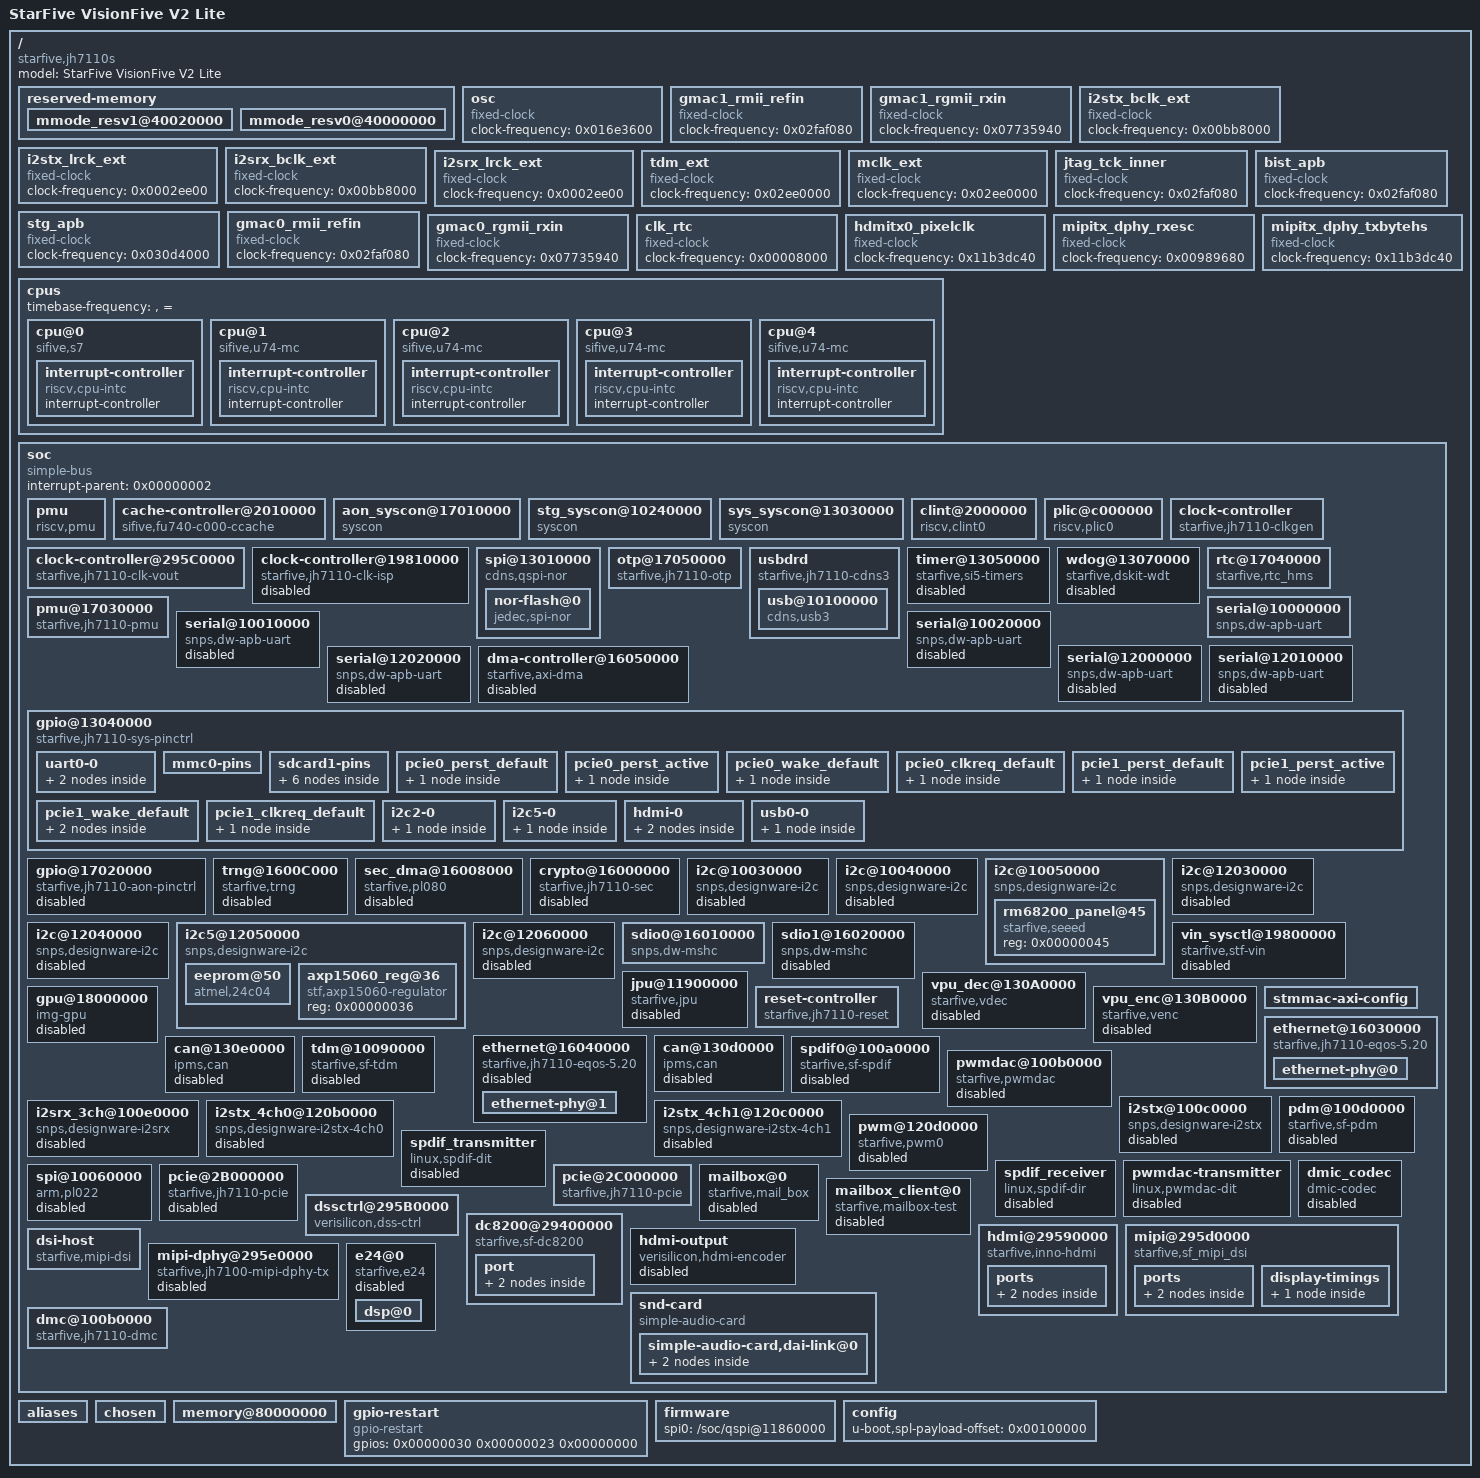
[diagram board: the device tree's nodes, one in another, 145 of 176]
/ {
	compatible = "starfive,jh7110s";
	#address-cells = <0x00000002>;
	#size-cells = <0x00000002>;
	model = "StarFive VisionFive V2 Lite";
	reserved-memory {
		#address-cells = <0x00000002>;
		#size-cells = <0x00000002>;
		ranges;
		mmode_resv1@40020000 {
			reg = <0x00000000 0x40020000 0x00000000 0x00020000>;
		};
		mmode_resv0@40000000 {
			reg = <0x00000000 0x40000000 0x00000000 0x00020000>;
		};
	};
	osc {
		compatible = "fixed-clock";
		#clock-cells = <0x00000000>;
		clock-frequency = <0x016e3600>;
		u-boot,dm-spl;
		phandle = <0x00000008>;
	};
	gmac1_rmii_refin {
		compatible = "fixed-clock";
		#clock-cells = <0x00000000>;
		clock-frequency = <0x02faf080>;
		u-boot,dm-spl;
		phandle = <0x00000009>;
	};
	gmac1_rgmii_rxin {
		compatible = "fixed-clock";
		#clock-cells = <0x00000000>;
		clock-frequency = <0x07735940>;
		phandle = <0x00000031>;
	};
	i2stx_bclk_ext {
		compatible = "fixed-clock";
		#clock-cells = <0x00000000>;
		clock-frequency = <0x00bb8000>;
		phandle = <0x00000032>;
	};
	i2stx_lrck_ext {
		compatible = "fixed-clock";
		#clock-cells = <0x00000000>;
		clock-frequency = <0x0002ee00>;
		phandle = <0x00000033>;
	};
	i2srx_bclk_ext {
		compatible = "fixed-clock";
		#clock-cells = <0x00000000>;
		clock-frequency = <0x00bb8000>;
		phandle = <0x00000034>;
	};
	i2srx_lrck_ext {
		compatible = "fixed-clock";
		#clock-cells = <0x00000000>;
		clock-frequency = <0x0002ee00>;
		phandle = <0x00000035>;
	};
	tdm_ext {
		compatible = "fixed-clock";
		#clock-cells = <0x00000000>;
		clock-frequency = <0x02ee0000>;
		phandle = <0x00000036>;
	};
	mclk_ext {
		compatible = "fixed-clock";
		#clock-cells = <0x00000000>;
		clock-frequency = <0x02ee0000>;
		phandle = <0x00000037>;
	};
	jtag_tck_inner {
		compatible = "fixed-clock";
		#clock-cells = <0x00000000>;
		clock-frequency = <0x02faf080>;
		phandle = <0x00000038>;
	};
	bist_apb {
		compatible = "fixed-clock";
		#clock-cells = <0x00000000>;
		clock-frequency = <0x02faf080>;
		phandle = <0x00000039>;
	};
	stg_apb {
		compatible = "fixed-clock";
		#clock-cells = <0x00000000>;
		clock-frequency = <0x030d4000>;
		u-boot,dm-spl;
		phandle = <0x0000000a>;
	};
	gmac0_rmii_refin {
		compatible = "fixed-clock";
		#clock-cells = <0x00000000>;
		clock-frequency = <0x02faf080>;
		u-boot,dm-spl;
		phandle = <0x0000000b>;
	};
	gmac0_rgmii_rxin {
		compatible = "fixed-clock";
		#clock-cells = <0x00000000>;
		clock-frequency = <0x07735940>;
		phandle = <0x0000003a>;
	};
	clk_rtc {
		compatible = "fixed-clock";
		#clock-cells = <0x00000000>;
		clock-frequency = <0x00008000>;
		phandle = <0x0000003b>;
	};
	hdmitx0_pixelclk {
		compatible = "fixed-clock";
		#clock-cells = <0x00000000>;
		clock-frequency = <0x11b3dc40>;
		phandle = <0x0000000c>;
	};
	mipitx_dphy_rxesc {
		compatible = "fixed-clock";
		#clock-cells = <0x00000000>;
		clock-frequency = <0x00989680>;
		phandle = <0x0000000d>;
	};
	mipitx_dphy_txbytehs {
		compatible = "fixed-clock";
		#clock-cells = <0x00000000>;
		clock-frequency = <0x11b3dc40>;
		phandle = <0x0000000e>;
	};
	cpus {
		#address-cells = <0x00000001>;
		#size-cells = <0x00000000>;
		u-boot,dm-spl;
		timebase-frequency = "", "=	";
		phandle = <0x0000003c>;
		cpu@0 {
			compatible = "sifive,s7", "riscv";
			reg = <0x00000000>;
			d-cache-block-size = <0x00000040>;
			d-cache-sets = <0x00000040>;
			d-cache-size = <0x00002000>;
			d-tlb-sets = <0x00000001>;
			d-tlb-size = <0x00000028>;
			device_type = "cpu";
			i-cache-block-size = <0x00000040>;
			i-cache-sets = <0x00000040>;
			i-cache-size = <0x00004000>;
			i-tlb-sets = <0x00000001>;
			i-tlb-size = <0x00000028>;
			mmu-type = "riscv,sv39";
			next-level-cache = <0x00000001>;
			riscv,isa = "rv64imacu_zba_zbb";
			tlb-split;
			status = "okay";
			u-boot,dm-spl;
			phandle = <0x0000003d>;
			interrupt-controller {
				#interrupt-cells = <0x00000001>;
				compatible = "riscv,cpu-intc";
				interrupt-controller;
				u-boot,dm-spl;
				phandle = <0x00000003>;
			};
		};
		cpu@1 {
			compatible = "sifive,u74-mc", "riscv";
			reg = <0x00000001>;
			d-cache-block-size = <0x00000040>;
			d-cache-sets = <0x00000040>;
			d-cache-size = <0x00008000>;
			d-tlb-sets = <0x00000001>;
			d-tlb-size = <0x00000028>;
			device_type = "cpu";
			i-cache-block-size = <0x00000040>;
			i-cache-sets = <0x00000040>;
			i-cache-size = <0x00008000>;
			i-tlb-sets = <0x00000001>;
			i-tlb-size = <0x00000028>;
			mmu-type = "riscv,sv39";
			next-level-cache = <0x00000001>;
			riscv,isa = "rv64imafdcbsux_zba_zbb";
			tlb-split;
			status = "okay";
			u-boot,dm-spl;
			phandle = <0x0000003e>;
			interrupt-controller {
				#interrupt-cells = <0x00000001>;
				compatible = "riscv,cpu-intc";
				interrupt-controller;
				u-boot,dm-spl;
				phandle = <0x00000004>;
			};
		};
		cpu@2 {
			compatible = "sifive,u74-mc", "riscv";
			reg = <0x00000002>;
			d-cache-block-size = <0x00000040>;
			d-cache-sets = <0x00000040>;
			d-cache-size = <0x00008000>;
			d-tlb-sets = <0x00000001>;
			d-tlb-size = <0x00000028>;
			device_type = "cpu";
			i-cache-block-size = <0x00000040>;
			i-cache-sets = <0x00000040>;
			i-cache-size = <0x00008000>;
			i-tlb-sets = <0x00000001>;
			i-tlb-size = <0x00000028>;
			mmu-type = "riscv,sv39";
			next-level-cache = <0x00000001>;
			riscv,isa = "rv64imafdcbsux_zba_zbb";
			tlb-split;
			status = "okay";
			u-boot,dm-spl;
			phandle = <0x0000003f>;
			interrupt-controller {
				#interrupt-cells = <0x00000001>;
				compatible = "riscv,cpu-intc";
				interrupt-controller;
				u-boot,dm-spl;
				phandle = <0x00000005>;
			};
		};
		cpu@3 {
			compatible = "sifive,u74-mc", "riscv";
			reg = <0x00000003>;
			d-cache-block-size = <0x00000040>;
			d-cache-sets = <0x00000040>;
			d-cache-size = <0x00008000>;
			d-tlb-sets = <0x00000001>;
			d-tlb-size = <0x00000028>;
			device_type = "cpu";
			i-cache-block-size = <0x00000040>;
			i-cache-sets = <0x00000040>;
			i-cache-size = <0x00008000>;
			i-tlb-sets = <0x00000001>;
			i-tlb-size = <0x00000028>;
			mmu-type = "riscv,sv39";
			next-level-cache = <0x00000001>;
			riscv,isa = "rv64imafdcbsux_zba_zbb";
			tlb-split;
			status = "okay";
			u-boot,dm-spl;
			phandle = <0x00000040>;
			interrupt-controller {
				#interrupt-cells = <0x00000001>;
				compatible = "riscv,cpu-intc";
				interrupt-controller;
				u-boot,dm-spl;
				phandle = <0x00000006>;
			};
		};
		cpu@4 {
			compatible = "sifive,u74-mc", "riscv";
			reg = <0x00000004>;
			d-cache-block-size = <0x00000040>;
			d-cache-sets = <0x00000040>;
			d-cache-size = <0x00008000>;
			d-tlb-sets = <0x00000001>;
			d-tlb-size = <0x00000028>;
			device_type = "cpu";
			i-cache-block-size = <0x00000040>;
			i-cache-sets = <0x00000040>;
			i-cache-size = <0x00008000>;
			i-tlb-sets = <0x00000001>;
			i-tlb-size = <0x00000028>;
			mmu-type = "riscv,sv39";
			next-level-cache = <0x00000001>;
			riscv,isa = "rv64imafdcbsux_zba_zbb";
			tlb-split;
			status = "okay";
			u-boot,dm-spl;
			phandle = <0x00000041>;
			interrupt-controller {
				#interrupt-cells = <0x00000001>;
				compatible = "riscv,cpu-intc";
				interrupt-controller;
				u-boot,dm-spl;
				phandle = <0x00000007>;
			};
		};
	};
	soc {
		compatible = "simple-bus";
		interrupt-parent = <0x00000002>;
		#address-cells = <0x00000002>;
		#size-cells = <0x00000002>;
		#clock-cells = <0x00000001>;
		ranges;
		u-boot,dm-spl;
		phandle = <0x00000042>;
		pmu {
			compatible = "riscv,pmu";
		};
		cache-controller@2010000 {
			compatible = "sifive,fu740-c000-ccache", "cache";
			reg = <0x00000000 0x02010000 0x00000000 0x00004000 0x00000000 0x02030000 0x00000000 0x00080000 0x00000000 0x08000000 0x00000000 0x02000000>;
			reg-names = "control", "prefetcher", "sideband";
			interrupts = <0x00000001 0x00000003 0x00000004 0x00000002>;
			cache-block-size = <0x00000040>;
			cache-level = <0x00000002>;
			cache-sets = <0x00000800>;
			cache-size = <0x00200000>;
			cache-unified;
			prefetch-dist-size = <0x00000004>;
			prefetch-hart-mask = <0x0000001e>;
			prefetch-enable;
			phandle = <0x00000001>;
		};
		aon_syscon@17010000 {
			compatible = "syscon";
			reg = <0x00000000 0x17010000 0x00000000 0x00001000>;
			phandle = <0x00000043>;
		};
		stg_syscon@10240000 {
			compatible = "syscon";
			reg = <0x00000000 0x10240000 0x00000000 0x00001000>;
			phandle = <0x00000011>;
		};
		sys_syscon@13030000 {
			compatible = "syscon";
			reg = <0x00000000 0x13030000 0x00000000 0x00001000>;
			phandle = <0x00000012>;
		};
		clint@2000000 {
			compatible = "riscv,clint0";
			reg = <0x00000000 0x02000000 0x00000000 0x00010000>;
			reg-names = "control";
			interrupts-extended = <0x00000003 0x00000003 0x00000003 0x00000007 0x00000004 0x00000003 0x00000004 0x00000007 0x00000005 0x00000003 0x00000005 0x00000007 0x00000006 0x00000003 0x00000006 0x00000007 0x00000007 0x00000003 0x00000007 0x00000007>;
			#interrupt-cells = <0x00000001>;
			u-boot,dm-spl;
			phandle = <0x00000044>;
		};
		plic@c000000 {
			compatible = "riscv,plic0";
			reg = <0x00000000 0x0c000000 0x00000000 0x04000000>;
			reg-names = "control";
			interrupts-extended = <0x00000003 0xffffffff 0x00000004 0xffffffff 0x00000004 0x00000009 0x00000005 0xffffffff 0x00000005 0x00000009 0x00000006 0xffffffff 0x00000006 0x00000009 0x00000007 0xffffffff 0x00000007 0x00000009>;
			interrupt-controller;
			#interrupt-cells = <0x00000001>;
			riscv,max-priority = <0x00000007>;
			riscv,ndev = <0x00000088>;
			phandle = <0x00000002>;
		};
		clock-controller {
			compatible = "starfive,jh7110-clkgen";
			reg = <0x00000000 0x13020000 0x00000000 0x00010000 0x00000000 0x10230000 0x00000000 0x00010000 0x00000000 0x17000000 0x00000000 0x00010000>;
			reg-names = "sys", "stg", "aon";
			clocks = <0x00000008 0x00000009 0x0000000a 0x0000000b>;
			clock-names = "osc", "gmac1_rmii_refin", "stg_apb", "gmac0_rmii_refin";
			#clock-cells = <0x00000001>;
			status = "okay";
			u-boot,dm-spl;
			phandle = <0x0000000f>;
		};
		clock-controller@295C0000 {
			compatible = "starfive,jh7110-clk-vout";
			reg = <0x00000000 0x295c0000 0x00000000 0x00010000>;
			reg-names = "vout";
			clocks = <0x0000000c 0x0000000d 0x0000000e>;
			clock-names = "hdmitx0_pixelclk", "mipitx_dphy_rxesc", "mipitx_dphy_txbytehs";
			#clock-cells = <0x00000001>;
			status = "okay";
			phandle = <0x00000025>;
		};
		clock-controller@19810000 {
			compatible = "starfive,jh7110-clk-isp";
			reg = <0x00000000 0x19810000 0x00000000 0x00010000>;
			reg-names = "isp";
			#clock-cells = <0x00000001>;
			clocks = <0x0000000f 0x0000010a 0x0000000f 0x00000033 0x0000000f 0x00000034>;
			clock-names = "u0_dom_isp_top_clk_dom_isp_top_clk_dvp", "u0_dom_isp_top_clk_dom_isp_top_clk_ispcore_2x", "u0_dom_isp_top_clk_dom_isp_top_clk_isp_axi";
			resets = <0x00000010 0x00000029 0x00000010 0x0000002a>;
			reset-names = "rst_isp_top_n", "rst_isp_top_axi";
			status = "disabled";
			phandle = <0x00000019>;
		};
		spi@13010000 {
			compatible = "cdns,qspi-nor";
			#address-cells = <0x00000001>;
			#size-cells = <0x00000000>;
			reg = <0x00000000 0x13010000 0x00000000 0x00010000 0x00000000 0x21000000 0x00000000 0x00400000>;
			clocks = <0x0000000f 0x0000005a>;
			clock-names = "clk_ref";
			resets = <0x00000010 0x0000003e 0x00000010 0x0000003d 0x00000010 0x0000003f>;
			resets-names = "rst_apb", "rst_ahb", "rst_ref";
			cdns,fifo-depth = <0x00000100>;
			cdns,fifo-width = <0x00000004>;
			spi-max-frequency = <0x0ee6b280>;
			status = "okay";
			u-boot,dm-spl;
			phandle = <0x00000045>;
			nor-flash@0 {
				compatible = "jedec,spi-nor";
				reg = <0x00000000>;
				spi-max-frequency = <0x05f5e100>;
				cdns,tshsl-ns = <0x00000001>;
				cdns,tsd2d-ns = <0x00000001>;
				cdns,tchsh-ns = <0x00000001>;
				cdns,tslch-ns = <0x00000001>;
				u-boot,dm-spl;
				phandle = <0x00000046>;
			};
		};
		otp@17050000 {
			compatible = "starfive,jh7110-otp";
			reg = <0x00000000 0x17050000 0x00000000 0x00010000>;
			clock-frequency = "", "=	";
			clocks = <0x0000000f 0x000000e4>;
			clock-names = "apb";
			phandle = <0x00000047>;
		};
		usbdrd {
			compatible = "starfive,jh7110-cdns3";
			dma-coherent;
			#address-cells = <0x00000002>;
			#size-cells = <0x00000002>;
			reg = <0x00000000 0x10210000 0x00000000 0x00001000 0x00000000 0x10200000 0x00000000 0x00001000>;
			clocks = <0x0000000f 0x0000005f 0x0000000f 0x000000c4 0x0000000f 0x000000c2 0x0000000f 0x000000c3 0x0000000f 0x000000bf 0x0000000f 0x000000c1 0x0000000f 0x000000c0 0x0000000f 0x000000c7>;
			clock-names = "125m", "app", "lpm", "stb", "apb", "axi", "utmi", "phy";
			resets = <0x00000010 0x0000008a 0x00000010 0x00000088 0x00000010 0x00000087 0x00000010 0x00000089 0x00000010 0x00000090>;
			reset-names = "pwrup", "apb", "axi", "utmi", "phy";
			starfive,stg-syscon = <0x00000011 0x00000004 0x000000c4 0x00000148 0x000001f4>;
			starfive,sys-syscon = <0x00000012 0x00000018>;
			status = "okay";
			starfive,usb2-only = <0x00000001>;
			pinctrl-names = "default";
			pinctrl-0 = <0x00000013>;
			phandle = <0x00000048>;
			usb@10100000 {
				compatible = "cdns,usb3";
				reg = <0x00000000 0x10100000 0x00000000 0x00010000 0x00000000 0x10110000 0x00000000 0x00010000 0x00000000 0x10120000 0x00000000 0x00010000>;
				reg-names = "otg", "xhci", "dev";
				interrupts = <0x00000064 0x0000006c 0x0000006e>;
				interrupt-names = "host", "peripheral", "otg";
				phy-names = "cdns3,usb3-phy", "cnds3,usb2-phy";
				maximum-speed = "super-speed";
				dr_mode = "unknown";
				dr_num_mode = <0x00000002>;
				phandle = <0x00000049>;
			};
		};
		timer@13050000 {
			compatible = "starfive,si5-timers";
			reg = <0x00000000 0x13050000 0x00000000 0x00010000>;
			interrupts = <0x00000045 0x00000046 0x00000047 0x00000048>;
			interrupt-names = "timer0", "timer1", "timer2", "timer3";
			clocks = <0x0000000f 0x0000007d 0x0000000f 0x0000007e 0x0000000f 0x0000007f 0x0000000f 0x00000080 0x0000000f 0x0000007c>;
			clock-names = "timer0", "timer1", "timer2", "timer3", "apb_clk";
			clock-frequency = <0x001e8480>;
			status = "disabled";
			phandle = <0x0000004a>;
		};
		wdog@13070000 {
			compatible = "starfive,dskit-wdt";
			reg = <0x00000000 0x13070000 0x00000000 0x00010000>;
			interrupts = <0x00000044>;
			interrupt-names = "wdog";
			clock-frequency = <0x001e8480>;
			clocks = <0x0000000f 0x0000007b 0x0000000f 0x0000007a>;
			clock-names = "core_clk", "apb_clk";
			resets = <0x00000010 0x0000006d 0x00000010 0x0000006e>;
			reset-names = "rst_apb", "rst_core";
			timeout-sec = <0x0000000f>;
			status = "disabled";
			phandle = <0x0000004b>;
		};
		rtc@17040000 {
			compatible = "starfive,rtc_hms";
			reg = <0x00000000 0x17040000 0x00000000 0x00010000>;
			interrupts = <0x0000000a 0x0000000b 0x0000000c>;
			interrupt-names = "rtc_ms_pulse", "rtc_sec_pulse", "rtc";
			clocks = <0x0000000f 0x000000e5 0x0000000f 0x000000e8>;
			clock-names = "pclk", "cal_clk";
			resets = <0x00000010 0x000000a5 0x00000010 0x000000a6 0x00000010 0x000000a7>;
			reset-names = "rst_apb", "rst_cal", "rst_osc";
			rtc,cal-clock-freq = <0x000f4240>;
			status = "okay";
			phandle = <0x0000004c>;
		};
		pmu@17030000 {
			compatible = "starfive,jh7110-pmu";
			reg = <0x00000000 0x17030000 0x00000000 0x00010000>;
			interrupts = <0x0000006f>;
			status = "okay";
			phandle = <0x0000004d>;
		};
		serial@10000000 {
			compatible = "snps,dw-apb-uart";
			reg = <0x00000000 0x10000000 0x00000000 0x00010000>;
			reg-io-width = <0x00000004>;
			reg-shift = <0x00000002>;
			clocks = <0x0000000f 0x00000092 0x0000000f 0x00000091>;
			clock-names = "baudclk", "apb_pclk";
			resets = <0x00000010 0x00000053 0x00000010 0x00000054>;
			interrupts = <0x00000020>;
			status = "okay";
			reg-offset = <0x00000000>;
			current-speed = <0x0001c200>;
			pinctrl-names = "default";
			pinctrl-0 = <0x00000014>;
			clock-frequency = <0x016e3600>;
			u-boot,dm-spl;
			phandle = <0x0000004e>;
		};
		serial@10010000 {
			compatible = "snps,dw-apb-uart";
			reg = <0x00000000 0x10010000 0x00000000 0x00010000>;
			reg-io-width = <0x00000004>;
			reg-shift = <0x00000002>;
			clocks = <0x0000000f 0x00000094 0x0000000f 0x00000093>;
			clock-names = "baudclk", "apb_pclk";
			resets = <0x00000010 0x00000055 0x00000010 0x00000056>;
			interrupts = <0x00000021>;
			status = "disabled";
			phandle = <0x0000004f>;
		};
		serial@10020000 {
			compatible = "snps,dw-apb-uart";
			reg = <0x00000000 0x10020000 0x00000000 0x00010000>;
			reg-io-width = <0x00000004>;
			reg-shift = <0x00000002>;
			clocks = <0x0000000f 0x00000096 0x0000000f 0x00000095>;
			clock-names = "baudclk", "apb_pclk";
			resets = <0x00000010 0x00000057 0x00000010 0x00000058>;
			interrupts = <0x00000022>;
			status = "disabled";
			phandle = <0x00000050>;
		};
		serial@12000000 {
			compatible = "snps,dw-apb-uart";
			reg = <0x00000000 0x12000000 0x00000000 0x00010000>;
			reg-io-width = <0x00000004>;
			reg-shift = <0x00000002>;
			clocks = <0x0000000f 0x00000098 0x0000000f 0x00000097>;
			clock-names = "baudclk", "apb_pclk";
			resets = <0x00000010 0x00000059 0x00000010 0x0000005a>;
			interrupts = <0x0000002d>;
			status = "disabled";
			phandle = <0x00000051>;
		};
		serial@12010000 {
			compatible = "snps,dw-apb-uart";
			reg = <0x00000000 0x12010000 0x00000000 0x00010000>;
			reg-io-width = <0x00000004>;
			reg-shift = <0x00000002>;
			clocks = <0x0000000f 0x0000009a 0x0000000f 0x00000099>;
			clock-names = "baudclk", "apb_pclk";
			resets = <0x00000010 0x0000005b 0x00000010 0x0000005c>;
			interrupts = <0x0000002e>;
			status = "disabled";
			phandle = <0x00000052>;
		};
		serial@12020000 {
			compatible = "snps,dw-apb-uart";
			reg = <0x00000000 0x12020000 0x00000000 0x00010000>;
			reg-io-width = <0x00000004>;
			reg-shift = <0x00000002>;
			clocks = <0x0000000f 0x0000009c 0x0000000f 0x0000009b>;
			clock-names = "baudclk", "apb_pclk";
			resets = <0x00000010 0x0000005d 0x00000010 0x0000005e>;
			interrupts = <0x0000002f>;
			status = "disabled";
			phandle = <0x00000053>;
		};
		dma-controller@16050000 {
			compatible = "starfive,axi-dma";
			reg = <0x00000000 0x16050000 0x00000000 0x00010000>;
			clocks = <0x0000000f 0x000000d9 0x0000000f 0x000000da>;
			clock-names = "core-clk", "cfgr-clk";
			resets = <0x00000010 0x00000085 0x00000010 0x00000086>;
			reset-names = "rst_axi", "rst_ahb";
			interrupts = <0x00000049>;
			#dma-cells = <0x00000002>;
			dma-channels = <0x00000004>;
			snps,dma-masters = <0x00000001>;
			snps,data-width = <0x00000003>;
			snps,num-hs-if = <0x00000038>;
			snps,block-size = <0x00010000 0x00010000 0x00010000 0x00010000>;
			snps,priority = <0x00000000 0x00000001 0x00000002 0x00000003>;
			snps,axi-max-burst-len = <0x00000010>;
			status = "disabled";
			phandle = <0x0000001b>;
		};
		gpio@13040000 {
			compatible = "starfive,jh7110-sys-pinctrl";
			reg = <0x00000000 0x13040000 0x00000000 0x00010000>;
			reg-names = "control";
			interrupts = <0x0000005b>;
			interrupt-controller;
			gpio-controller;
			#gpio-cells = <0x00000002>;
			ngpios = <0x00000040>;
			status = "okay";
			u-boot,dm-spl;
			phandle = <0x00000030>;
			uart0-0 {
				phandle = <0x00000014>;
				tx-pins {
					pinmux = <0xff140005>;
					bias-disable;
					drive-strength = <0x0000000c>;
					input-disable;
					input-schmitt-disable;
					slew-rate = <0x00000000>;
				};
				rx-pins {
					pinmux = <0x0e000406>;
					bias-pull-up;
					drive-strength = <0x00000002>;
					input-enable;
					input-schmitt-enable;
					slew-rate = <0x00000000>;
				};
			};
			mmc0-pins {
				phandle = <0x00000017>;
			};
			sdcard1-pins {
				phandle = <0x00000018>;
				sdcard1-pins0 {
					pinmux = "ÿ7", "
";
					bias-pull-up;
					drive-strength = <0x0000000c>;
					input-disable;
					input-schmitt-disable;
					slew-rate = <0x00000000>;
				};
				sdcard1-pins1 {
					pinmux = <0x2c394c09>;
					bias-pull-up;
					drive-strength = <0x0000000c>;
					input-enable;
					input-schmitt-enable;
					slew-rate = <0x00000000>;
				};
				sdcard1-pins2 {
					pinmux = <0x2d3a500b>;
					bias-pull-up;
					drive-strength = <0x0000000c>;
					input-enable;
					input-schmitt-enable;
					slew-rate = <0x00000000>;
				};
				sdcard1-pins3 {
					pinmux = <0x2e3b540c>;
					bias-pull-up;
					drive-strength = <0x0000000c>;
					input-enable;
					input-schmitt-enable;
					slew-rate = <0x00000000>;
				};
				sdcard1-pins4 {
					pinmux = <0x2f3c5807>;
					bias-pull-up;
					drive-strength = <0x0000000c>;
					input-enable;
					input-schmitt-enable;
					slew-rate = <0x00000000>;
				};
				sdcard1-pins5 {
					pinmux = <0x303d5c08>;
					bias-pull-up;
					drive-strength = <0x0000000c>;
					input-enable;
					input-schmitt-enable;
					slew-rate = <0x00000000>;
				};
			};
			pcie0_perst_default {
				phandle = <0x0000001c>;
				perst-pins {
					pinmux = <0xff01001a>;
					drive-strength = <0x00000002>;
					input-disable;
					input-schmitt-disable;
					slew-rate = <0x00000000>;
				};
			};
			pcie0_perst_active {
				phandle = <0x0000001d>;
				perst-pins {
					pinmux = <0xff00001a>;
					drive-strength = <0x00000002>;
					input-disable;
					input-schmitt-disable;
					slew-rate = <0x00000000>;
				};
			};
			pcie0_wake_default {
				phandle = <0x0000001e>;
				wake-pins {
					pinmux = <0xff010020>;
					drive-strength = <0x00000002>;
					input-enable;
					input-schmitt-disable;
					slew-rate = <0x00000000>;
				};
			};
			pcie0_clkreq_default {
				phandle = <0x0000001f>;
				clkreq-pins {
					pinmux = <0xff01001b>;
					drive-strength = <0x00000002>;
					input-enable;
					input-schmitt-disable;
					slew-rate = <0x00000000>;
				};
			};
			pcie1_perst_default {
				phandle = <0x00000020>;
				perst-pins {
					pinmux = <0xff01001c>;
					drive-strength = <0x00000002>;
					input-disable;
					input-schmitt-disable;
					slew-rate = <0x00000000>;
				};
			};
			pcie1_perst_active {
				phandle = <0x00000021>;
				perst-pins {
					pinmux = <0xff00001c>;
					drive-strength = <0x00000002>;
					input-disable;
					input-schmitt-disable;
					slew-rate = <0x00000000>;
				};
			};
			pcie1_wake_default {
				phandle = <0x00000022>;
				wake-pins {
					pinmux = <0xff010015>;
					drive-strength = <0x00000002>;
					input-enable;
					input-schmitt-disable;
					slew-rate = <0x00000000>;
				};
				power-pins {
					pinmux = <0xff01001b>;
					input-disable;
				};
			};
			pcie1_clkreq_default {
				phandle = <0x00000023>;
				clkreq-pins {
					pinmux = <0xff01001d>;
					drive-strength = <0x00000002>;
					input-enable;
					input-schmitt-disable;
					slew-rate = <0x00000000>;
				};
			};
			i2c2-0 {
				phandle = <0x00000016>;
				i2c-pins {
					pinmux = <0x3b007803 0x3c007c02>;
					bias-disable;
					input-enable;
					input-schmitt-enable;
				};
			};
			i2c5-0 {
				phandle = <0x00000054>;
				i2c-pins {
					pinmux = <0x4f00a813 0x5000ac14>;
					bias-disable;
					input-enable;
					input-schmitt-enable;
				};
			};
			hdmi-0 {
				phandle = <0x00000028>;
				cec-pins {
					pinmux = <0x050a080e>;
					bias-pull-up;
					input-enable;
				};
				hpd-pins {
					pinmux = <0x0800040f>;
					input-enable;
				};
			};
			usb0-0 {
				phandle = <0x00000013>;
				power-pins {
					pinmux = <0xff01001a>;
					input-disable;
				};
			};
		};
		gpio@17020000 {
			compatible = "starfive,jh7110-aon-pinctrl";
			reg = <0x00000000 0x17020000 0x00000000 0x00010000>;
			reg-names = "control";
			interrupts = <0x0000005a>;
			interrupt-controller;
			gpio-controller;
			#gpio-cells = <0x00000002>;
			ngpios = <0x00000004>;
			status = "disabled";
			u-boot,dm-spl;
			phandle = <0x00000055>;
		};
		trng@1600C000 {
			compatible = "starfive,trng";
			reg = <0x00000000 0x1600c000 0x00000000 0x00004000>;
			clocks = <0x0000000f 0x000000cd 0x0000000f 0x000000ce>;
			clock-names = "hclk", "miscahb_clk";
			resets = <0x00000010 0x00000083>;
			interrupts = <0x0000001e>;
			status = "disabled";
			phandle = <0x00000056>;
		};
		sec_dma@16008000 {
			compatible = "starfive,pl080";
			reg = <0x00000000 0x16008000 0x00000000 0x00004000>;
			reg-names = "sec_dma";
			interrupts = <0x0000001d>;
			clocks = <0x0000000f 0x000000cd 0x0000000f 0x000000ce>;
			clock-names = "sec_hclk", "sec_ahb";
			resets = <0x00000010 0x00000083>;
			reset-names = "sec_hre";
			lli-bus-interface-ahb1;
			mem-bus-interface-ahb1;
			memcpy-burst-size = <0x00000100>;
			memcpy-bus-width = <0x00000020>;
			#dma-cells = <0x00000002>;
			status = "disabled";
			phandle = <0x00000015>;
		};
		crypto@16000000 {
			compatible = "starfive,jh7110-sec";
			reg = <0x00000000 0x16000000 0x00000000 0x00004000 0x00000000 0x16008000 0x00000000 0x00004000>;
			reg-names = "secreg", "secdma";
			interrupts = <0x0000001c 0x0000001d>;
			interrupt-names = "secirq", "dmairq";
			clocks = <0x0000000f 0x000000cd 0x0000000f 0x000000ce>;
			clock-names = "sec_hclk", "sec_ahb";
			resets = <0x00000010 0x00000083>;
			reset-names = "sec_hre";
			enable-dma = "true";
			dmas = <0x00000015 0x00000001 0x00000002 0x00000015 0x00000000 0x00000002>;
			dma-names = "sec_m", "sec_p";
			status = "disabled";
			phandle = <0x00000057>;
		};
		i2c@10030000 {
			compatible = "snps,designware-i2c";
			reg = <0x00000000 0x10030000 0x00000000 0x00010000>;
			clocks = <0x0000000f 0x0000008a>;
			clock-names = "pclk";
			resets = <0x00000010 0x0000004c>;
			interrupts = <0x00000023>;
			#address-cells = <0x00000001>;
			#size-cells = <0x00000000>;
			status = "disabled";
			phandle = <0x00000058>;
		};
		i2c@10040000 {
			compatible = "snps,designware-i2c";
			reg = <0x00000000 0x10040000 0x00000000 0x00010000>;
			clocks = <0x0000000f 0x0000008b>;
			clock-names = "pclk";
			resets = <0x00000010 0x0000004d>;
			interrupts = <0x00000024>;
			#address-cells = <0x00000001>;
			#size-cells = <0x00000000>;
			status = "disabled";
			phandle = <0x00000059>;
		};
		i2c@10050000 {
			compatible = "snps,designware-i2c";
			reg = <0x00000000 0x10050000 0x00000000 0x00010000>;
			clocks = <0x0000000f 0x0000008c>;
			clock-names = "pclk";
			resets = <0x00000010 0x0000004e>;
			interrupts = <0x00000025>;
			#address-cells = <0x00000001>;
			#size-cells = <0x00000000>;
			status = "okay";
			clock-frequency = <0x000186a0>;
			i2c-sda-hold-time-ns = <0x0000012c>;
			i2c-sda-falling-time-ns = <0x00000bb8>;
			i2c-scl-falling-time-ns = <0x00000bb8>;
			auto_calc_scl_lhcnt;
			pinctrl-names = "default";
			pinctrl-0 = <0x00000016>;
			phandle = <0x0000005a>;
			rm68200_panel@45 {
				compatible = "starfive,seeed";
				reg = <0x00000045>;
				phandle = <0x0000002a>;
			};
		};
		i2c@12030000 {
			compatible = "snps,designware-i2c";
			reg = <0x00000000 0x12030000 0x00000000 0x00010000>;
			clocks = <0x0000000f 0x0000008d>;
			clock-names = "pclk";
			resets = <0x00000010 0x0000004f>;
			interrupts = <0x00000030>;
			#address-cells = <0x00000001>;
			#size-cells = <0x00000000>;
			status = "disabled";
			phandle = <0x0000005b>;
		};
		i2c@12040000 {
			compatible = "snps,designware-i2c";
			reg = <0x00000000 0x12040000 0x00000000 0x00010000>;
			clocks = <0x0000000f 0x0000008e>;
			clock-names = "pclk";
			resets = <0x00000010 0x00000050>;
			interrupts = <0x00000031>;
			#address-cells = <0x00000001>;
			#size-cells = <0x00000000>;
			status = "disabled";
			phandle = <0x0000005c>;
		};
		i2c5@12050000 {
			compatible = "snps,designware-i2c";
			reg = <0x00000000 0x12050000 0x00000000 0x00010000>;
			clocks = <0x0000000f 0x0000008f>;
			clock-names = "pclk";
			resets = <0x00000010 0x00000051>;
			interrupts = <0x00000032>;
			#address-cells = <0x00000001>;
			#size-cells = <0x00000000>;
			status = "okay";
			clock-frequency = <0x000186a0>;
			i2c-sda-hold-time-ns = <0x0000012c>;
			i2c-sda-falling-time-ns = <0x00000bb8>;
			i2c-scl-falling-time-ns = <0x00000bb8>;
			auto_calc_scl_lhcnt;
			u-boot,dm-spl;
			phandle = <0x0000005d>;
			eeprom@50 {
				compatible = "atmel,24c04";
				reg = <0x00000050>;
				pagesize = <0x00000010>;
				u-boot,dm-spl;
			};
			axp15060_reg@36 {
				compatible = "stf,axp15060-regulator";
				reg = <0x00000036>;
				phandle = <0x0000005e>;
			};
		};
		i2c@12060000 {
			compatible = "snps,designware-i2c";
			reg = <0x00000000 0x12060000 0x00000000 0x00010000>;
			clocks = <0x0000000f 0x00000090>;
			clock-names = "pclk";
			resets = <0x00000010 0x00000052>;
			interrupts = <0x00000033>;
			#address-cells = <0x00000001>;
			#size-cells = <0x00000000>;
			status = "disabled";
			phandle = <0x0000005f>;
		};
		sdio0@16010000 {
			compatible = "snps,dw-mshc";
			reg = <0x00000000 0x16010000 0x00000000 0x00010000>;
			clocks = <0x0000000f 0x0000005b 0x0000000f 0x0000005d>;
			clock-names = "biu", "ciu";
			resets = <0x00000010 0x00000040>;
			reset-names = "reset";
			assigned-clocks = <0x0000000f 0x0000005d>;
			assigned-clock-rates = <0x02faf080>;
			fifo-depth = <0x00000020>;
			bus-width = <0x00000008>;
			pinctrl-names = "default";
			pinctrl-0 = <0x00000017>;
			status = "okay";
			u-boot,dm-spl;
			phandle = <0x00000060>;
		};
		sdio1@16020000 {
			compatible = "snps,dw-mshc";
			reg = <0x00000000 0x16020000 0x00000000 0x00010000>;
			clocks = <0x0000000f 0x0000005c 0x0000000f 0x0000005e>;
			clock-names = "biu", "ciu";
			resets = <0x00000010 0x00000041>;
			reset-names = "reset";
			assigned-clocks = <0x0000000f 0x0000005e>;
			assigned-clock-rates = <0x02faf080>;
			fifo-depth = <0x00000020>;
			bus-width = <0x00000004>;
			pinctrl-names = "default";
			pinctrl-0 = <0x00000018>;
			status = "disabled";
			u-boot,dm-spl;
			phandle = <0x00000061>;
		};
		vin_sysctl@19800000 {
			compatible = "starfive,stf-vin";
			reg = <0x00000000 0x19800000 0x00000000 0x00010000 0x00000000 0x19810000 0x00000000 0x00010000 0x00000000 0x19820000 0x00000000 0x00010000 0x00000000 0x19830000 0x00000000 0x00010000 0x00000000 0x19840000 0x00000000 0x00010000 0x00000000 0x19870000 0x00000000 0x00030000 0x00000000 0x198a0000 0x00000000 0x00030000 0x00000000 0x11840000 0x00000000 0x00010000 0x00000000 0x17030000 0x00000000 0x00010000 0x00000000 0x13020000 0x00000000 0x00010000>;
			reg-names = "mipi0", "vclk", "vrst", "mipi1", "sctrl", "isp0", "isp1", "trst", "pmu", "syscrg";
			clocks = <0x00000019 0x00000000 0x00000019 0x00000006 0x00000019 0x00000007 0x00000019 0x0000000d 0x00000019 0x00000002 0x00000019 0x0000000c 0x00000019 0x00000001 0x00000019 0x00000008 0x00000019 0x00000009 0x00000019 0x0000000a 0x00000019 0x0000000b>;
			clock-names = "clk_apb_func", "clk_pclk", "clk_sys_clk", "clk_wrapper_clk_c", "clk_dvp_inv", "clk_axiwr", "clk_mipi_rx0_pxl", "clk_pixel_clk_if0", "clk_pixel_clk_if1", "clk_pixel_clk_if2", "clk_pixel_clk_if3";
			resets = <0x00000010 0x000000c0 0x00000010 0x000000c1 0x00000010 0x000000c4 0x00000010 0x000000c9 0x00000010 0x000000ca 0x00000010 0x000000cb 0x00000010 0x000000c5 0x00000010 0x000000c6 0x00000010 0x000000c7 0x00000010 0x000000c8 0x00000010 0x000000c2 0x00000010 0x000000c3>;
			reset-names = "rst_wrapper_p", "rst_wrapper_c", "rst_pclk", "rst_sys_clk", "rst_axird", "rst_axiwr", "rst_pixel_clk_if0", "rst_pixel_clk_if1", "rst_pixel_clk_if2", "rst_pixel_clk_if3", "rst_m31dphy_hw", "rst_m31dphy_b09_always_on";
			interrupts = <0x0000005c 0x00000057 0x00000056>;
			status = "disabled";
			phandle = <0x00000062>;
		};
		jpu@11900000 {
			compatible = "starfive,jpu";
			reg = <0x00000000 0x13090000 0x00000000 0x00000300>;
			interrupts = <0x0000000e>;
			clocks = <0x0000000f 0x00000042 0x0000000f 0x00000043 0x0000000f 0x00000044>;
			clock-names = "axi_clk", "core_clk", "apb_clk";
			resets = <0x00000010 0x0000002c 0x00000010 0x0000002d 0x00000010 0x0000002e>;
			reset-names = "rst_axi", "rst_core", "rst_apb";
			status = "disabled";
			phandle = <0x00000063>;
		};
		vpu_dec@130A0000 {
			compatible = "starfive,vdec";
			reg = <0x00000000 0x130a0000 0x00000000 0x00010000>;
			interrupts = <0x0000000d>;
			clocks = <0x0000000f 0x00000046 0x0000000f 0x00000047 0x0000000f 0x00000048 0x0000000f 0x00000049 0x0000000f 0x0000004c>;
			clock-names = "axi_clk", "bpu_clk", "vce_clk", "apb_clk", "noc_bus";
			resets = <0x00000010 0x0000002f 0x00000010 0x00000030 0x00000010 0x00000031 0x00000010 0x00000032 0x00000010 0x00000035>;
			reset-names = "rst_axi", "rst_bpu", "rst_vce", "rst_apb", "rst_sram";
			starfive,vdec_noc_ctrl;
			status = "disabled";
			phandle = <0x00000064>;
		};
		vpu_enc@130B0000 {
			compatible = "starfive,venc";
			reg = <0x00000000 0x130b0000 0x00000000 0x00010000>;
			interrupts = <0x0000000f>;
			clocks = <0x0000000f 0x0000004e 0x0000000f 0x0000004f 0x0000000f 0x00000050 0x0000000f 0x00000051 0x0000000f 0x00000052>;
			clock-names = "axi_clk", "bpu_clk", "vce_clk", "apb_clk", "noc_bus";
			resets = <0x00000010 0x00000036 0x00000010 0x00000037 0x00000010 0x00000038 0x00000010 0x00000039 0x00000010 0x0000003a>;
			reset-names = "rst_axi", "rst_bpu", "rst_vce", "rst_apb", "rst_sram";
			starfive,venc_noc_ctrl;
			status = "disabled";
			phandle = <0x00000065>;
		};
		reset-controller {
			compatible = "starfive,jh7110-reset";
			reg = <0x00000000 0x13020000 0x00000000 0x00010000 0x00000000 0x10230000 0x00000000 0x00010000 0x00000000 0x17000000 0x00000000 0x00010000 0x00000000 0x19810000 0x00000000 0x00010000 0x00000000 0x295c0000 0x00000000 0x00010000>;
			reg-names = "syscrg", "stgcrg", "aoncrg", "ispcrg", "voutcrg";
			#reset-cells = <0x00000001>;
			status = "okay";
			u-boot,dm-spl;
			phandle = <0x00000010>;
		};
		stmmac-axi-config {
			snps,wr_osr_lmt = <0x0000000f>;
			snps,rd_osr_lmt = <0x0000000f>;
			snps,blen = <0x00000100 0x00000080 0x00000040 0x00000020 0x00000000 0x00000000 0x00000000>;
			phandle = <0x0000001a>;
		};
		ethernet@16030000 {
			compatible = "starfive,jh7110-eqos-5.20";
			reg = <0x00000000 0x16030000 0x00000000 0x00010000>;
			clock-names = "gtx", "tx", "ptp_ref", "stmmaceth", "pclk", "gtxc", "rmii_rtx";
			clocks = <0x0000000f 0x0000006c 0x0000000f 0x000000e0 0x0000000f 0x0000006d 0x0000000f 0x000000dd 0x0000000f 0x000000de 0x0000000f 0x0000006f 0x0000000f 0x000000df>;
			resets = <0x00000010 0x000000a1 0x00000010 0x000000a0>;
			reset-names = "ahb", "stmmaceth";
			interrupts = <0x00000007 0x00000006 0x00000005>;
			interrupt-names = "macirq", "eth_wake_irq", "eth_lpi";
			max-frame-size = <0x00002328>;
			phy-mode = "rgmii-id";
			snps,multicast-filter-bins = <0x00000100>;
			snps,perfect-filter-entries = <0x00000080>;
			rx-fifo-depth = <0x00040000>;
			tx-fifo-depth = <0x00020000>;
			snps,fixed-burst;
			snps,no-pbl-x8;
			snps,force_thresh_dma_mode;
			snps,axi-config = <0x0000001a>;
			snps,tso;
			snps,en-tx-lpi-clockgating;
			snps,en-lpi;
			snps,write-requests = <0x00000002>;
			snps,read-requests = <0x00000010>;
			snps,burst-map = <0x00000007>;
			snps,txpbl = <0x00000010>;
			snps,rxpbl = <0x00000010>;
			status = "okay";
			#address-cells = <0x00000001>;
			#size-cells = <0x00000000>;
			phandle = <0x00000066>;
			ethernet-phy@0 {
				rgmii_sw_dr_2 = <0x00000000>;
				rgmii_sw_dr = <0x00000003>;
				rgmii_sw_dr_rxc = <0x00000006>;
				rxc_dly_en = <0x00000000>;
				rx_delay_sel = <0x0000000a>;
				tx_delay_sel_fe = <0x00000005>;
				tx_delay_sel = <0x0000000a>;
				tx_inverted_10 = <0x00000001>;
				tx_inverted_100 = <0x00000001>;
				tx_inverted_1000 = <0x00000001>;
				phandle = <0x00000067>;
			};
		};
		ethernet@16040000 {
			compatible = "starfive,jh7110-eqos-5.20";
			reg = <0x00000000 0x16040000 0x00000000 0x00010000>;
			clock-names = "gtx", "tx", "ptp_ref", "stmmaceth", "pclk", "gtxc", "rmii_rtx";
			clocks = <0x0000000f 0x00000064 0x0000000f 0x00000069 0x0000000f 0x00000066 0x0000000f 0x00000061 0x0000000f 0x00000062 0x0000000f 0x0000006b 0x0000000f 0x00000065>;
			resets = <0x00000010 0x00000043 0x00000010 0x00000042>;
			reset-names = "ahb", "stmmaceth";
			interrupts = <0x0000004e 0x0000004d 0x0000004c>;
			interrupt-names = "macirq", "eth_wake_irq", "eth_lpi";
			max-frame-size = <0x00002328>;
			phy-mode = "rgmii-id";
			snps,multicast-filter-bins = <0x00000100>;
			snps,perfect-filter-entries = <0x00000080>;
			rx-fifo-depth = <0x00040000>;
			tx-fifo-depth = <0x00020000>;
			snps,fixed-burst;
			snps,no-pbl-x8;
			snps,force_thresh_dma_mode;
			snps,axi-config = <0x0000001a>;
			snps,tso;
			snps,en-tx-lpi-clockgating;
			snps,en-lpi;
			snps,write-requests = <0x00000002>;
			snps,read-requests = <0x00000010>;
			snps,burst-map = <0x00000007>;
			snps,txpbl = <0x00000010>;
			snps,rxpbl = <0x00000010>;
			status = "disabled";
			#address-cells = <0x00000001>;
			#size-cells = <0x00000000>;
			phandle = <0x00000068>;
			ethernet-phy@1 {
				rgmii_sw_dr_2 = <0x00000000>;
				rgmii_sw_dr = <0x00000003>;
				rgmii_sw_dr_rxc = <0x00000006>;
				tx_delay_sel_fe = <0x00000005>;
				tx_delay_sel = <0x00000000>;
				rxc_dly_en = <0x00000000>;
				rx_delay_sel = <0x00000002>;
				tx_inverted_10 = <0x00000001>;
				tx_inverted_100 = <0x00000001>;
				tx_inverted_1000 = <0x00000000>;
				phandle = <0x00000069>;
			};
		};
		gpu@18000000 {
			compatible = "img-gpu";
			reg = <0x00000000 0x18000000 0x00000000 0x00100000 0x00000000 0x0130c000 0x00000000 0x00010000>;
			clocks = <0x0000000f 0x00000030 0x0000000f 0x00000031 0x0000000f 0x0000002e 0x0000000f 0x0000002f 0x0000000f 0x00000032>;
			clock-names = "clk_apb", "clk_rtc", "clk_core", "clk_sys", "clk_axi";
			resets = <0x00000010 0x00000015 0x00000010 0x00000016>;
			reset-names = "rst_apb", "rst_doma";
			interrupts = <0x00000052>;
			current-clock = <0x007a1200>;
			status = "disabled";
			phandle = <0x0000006a>;
		};
		can@130d0000 {
			compatible = "ipms,can";
			reg = <0x00000000 0x130d0000 0x00000000 0x00001000>;
			interrupts = <0x00000070>;
			clocks = <0x0000000f 0x00000073 0x0000000f 0x00000075 0x0000000f 0x00000074>;
			clock-names = "apb_clk", "core_clk", "timer_clk";
			resets = <0x00000010 0x0000006f 0x00000010 0x00000070 0x00000010 0x00000071>;
			reset-names = "rst_apb", "rst_core", "rst_timer";
			starfive,sys-syscon = <0x00000012 0x00000010 0x00000003 0x00000008>;
			syscon,can_or_canfd = <0x00000000>;
			status = "disabled";
			phandle = <0x0000006b>;
		};
		can@130e0000 {
			compatible = "ipms,can";
			reg = <0x00000000 0x130e0000 0x00000000 0x00001000>;
			interrupts = <0x00000071>;
			clocks = <0x0000000f 0x00000076 0x0000000f 0x00000078 0x0000000f 0x00000077>;
			clock-names = "apb_clk", "core_clk", "timer_clk";
			resets = <0x00000010 0x00000072 0x00000010 0x00000073 0x00000010 0x00000074>;
			reset-names = "rst_apb", "rst_core", "rst_timer";
			starfive,sys-syscon = <0x00000012 0x00000088 0x00000012 0x00040000>;
			syscon,can_or_canfd = <0x00000000>;
			status = "disabled";
			phandle = <0x0000006c>;
		};
		tdm@10090000 {
			compatible = "starfive,sf-tdm";
			reg = <0x00000000 0x10090000 0x00000000 0x00001000>;
			reg-names = "tdm";
			clocks = <0x0000000f 0x00000009 0x0000000f 0x000000b8 0x0000000f 0x0000000c 0x0000000f 0x000000b9 0x0000000f 0x000000ba>;
			clock-names = "clk_ahb0", "clk_tdm_ahb", "clk_apb0", "clk_tdm_apb", "clk_tdm_intl";
			resets = <0x00000010 0x00000069 0x00000010 0x0000006b 0x00000010 0x0000006a>;
			reset-names = "tdm_ahb", "tdm_apb", "tdm_rst";
			dmas = <0x0000001b 0x00000014 0x00000001 0x0000001b 0x00000015 0x00000001>;
			dma-names = "rx", "tx";
			#sound-dai-cells = <0x00000000>;
			status = "disabled";
			phandle = <0x0000006d>;
		};
		spdif0@100a0000 {
			compatible = "starfive,sf-spdif";
			reg = <0x00000000 0x100a0000 0x00000000 0x00001000>;
			clocks = <0x0000000f 0x0000009f 0x0000000f 0x000000a0 0x0000000f 0x00000012>;
			clock-names = "spdif-apb", "spdif-core", "audioclk";
			resets = <0x00000010 0x0000005f>;
			reset-names = "rst_apb";
			interrupts = <0x00000054>;
			interrupt-names = "tx";
			#sound-dai-cells = <0x00000000>;
			status = "disabled";
			phandle = <0x0000006e>;
		};
		pwmdac@100b0000 {
			compatible = "starfive,pwmdac";
			reg = <0x00000000 0x100b0000 0x00000000 0x00001000>;
			clocks = <0x0000000f 0x0000000c 0x0000000f 0x0000009d 0x0000000f 0x0000009e>;
			clock-names = "apb0", "pwmdac-apb", "pwmdac-core";
			resets = <0x00000010 0x00000060>;
			reset-names = "rst-apb";
			dmas = <0x0000001b 0x00000016 0x00000001>;
			dma-names = "tx";
			#sound-dai-cells = <0x00000000>;
			status = "disabled";
			phandle = <0x0000002e>;
		};
		i2stx@100c0000 {
			compatible = "snps,designware-i2stx";
			reg = <0x00000000 0x100c0000 0x00000000 0x00001000>;
			clocks = <0x0000000f 0x0000000c>;
			clock-names = "i2sclk";
			interrupt-names = "tx";
			#sound-dai-cells = <0x00000000>;
			dmas = <0x0000001b 0x0000001c 0x00000001>;
			dma-names = "rx";
			status = "disabled";
			phandle = <0x0000006f>;
		};
		pdm@100d0000 {
			compatible = "starfive,sf-pdm";
			reg = <0x00000000 0x100d0000 0x00000000 0x00001000>;
			reg-names = "pdm";
			clocks = <0x0000000f 0x000000b6 0x0000000f 0x0000000c 0x0000000f 0x000000b7 0x0000000f 0x00000130 0x0000000f 0x00000131 0x0000000f 0x00000132 0x0000000f 0x00000133 0x0000000f 0x000000b3>;
			clock-names = "pdm_dmic", "clk_apb0", "pdm_apb", "pdm_dmic0_bclk", "pdm_dmic0_lrck", "pdm_dmic1_bclk", "pdm_dmic1_lrck", "u0_i2srx_3ch_bclk";
			resets = <0x00000010 0x00000061 0x00000010 0x00000062>;
			reset-names = "pdm_dmic", "pdm_apb";
			#sound-dai-cells = <0x00000000>;
			status = "disabled";
			phandle = <0x00000070>;
		};
		i2srx_3ch@100e0000 {
			compatible = "snps,designware-i2srx";
			reg = <0x00000000 0x100e0000 0x00000000 0x00001000>;
			clocks = <0x0000000f 0x0000000c 0x0000000f 0x000000af 0x0000000f 0x000000b0>;
			clock-names = "apb0", "3ch-apb", "3ch-bclk";
			resets = <0x00000010 0x00000063 0x00000010 0x00000064>;
			reset-names = "rst_apb_rx", "rst_bclk_rx";
			interrupts = <0x0000002a>;
			interrupt-names = "rx";
			dmas = <0x0000001b 0x00000018 0x00000001>;
			dma-names = "rx";
			#sound-dai-cells = <0x00000000>;
			status = "disabled";
			phandle = <0x00000071>;
		};
		i2stx_4ch0@120b0000 {
			compatible = "snps,designware-i2stx-4ch0";
			reg = <0x00000000 0x120b0000 0x00000000 0x00001000>;
			clocks = <0x0000000f 0x00000011 0x0000000f 0x000000a2 0x0000000f 0x000000a4 0x0000000f 0x00000012 0x0000000f 0x000000a5 0x0000000f 0x000000a7>;
			clock-names = "inner", "bclk-mst", "lrck-mst", "mclk", "bclk0", "lrck0";
			resets = <0x00000010 0x00000065 0x00000010 0x00000066>;
			reset-names = "rst_apb0", "rst_bclk0";
			interrupts = <0x0000003a>;
			interrupt-names = "tx";
			dmas = <0x0000001b 0x0000002f 0x00000001>;
			dma-names = "tx";
			#sound-dai-cells = <0x00000000>;
			status = "disabled";
			phandle = <0x00000072>;
		};
		i2stx_4ch1@120c0000 {
			compatible = "snps,designware-i2stx-4ch1";
			reg = <0x00000000 0x120c0000 0x00000000 0x00001000>;
			clocks = <0x0000000f 0x00000011 0x0000000f 0x000000a9 0x0000000f 0x000000ab 0x0000000f 0x00000012 0x0000000f 0x000000ac 0x0000000f 0x000000ae>;
			clock-names = "inner", "bclk-mst1", "lrck-mst1", "mclk", "bclk1", "lrck1";
			resets = <0x00000010 0x00000067 0x00000010 0x00000068>;
			reset-names = "rst_apb1", "rst_bclk1";
			interrupts = <0x0000003b>;
			interrupt-names = "tx";
			dmas = <0x0000001b 0x00000030 0x00000001>;
			dma-names = "tx";
			#sound-dai-cells = <0x00000000>;
			status = "disabled";
			phandle = <0x00000073>;
		};
		pwm@120d0000 {
			compatible = "starfive,pwm0";
			reg = <0x00000000 0x120d0000 0x00000000 0x00010000>;
			reg-names = "control";
			clocks = <0x0000000f 0x00000079>;
			resets = <0x00000010 0x0000006c>;
			starfive,approx-period = <0x001e8480>;
			#pwm-cells = <0x00000003>;
			starfive,npwm = <0x00000008>;
			status = "disabled";
			phandle = <0x00000074>;
		};
		spdif_transmitter {
			compatible = "linux,spdif-dit";
			#sound-dai-cells = <0x00000000>;
			status = "disabled";
			phandle = <0x00000075>;
		};
		spdif_receiver {
			compatible = "linux,spdif-dir";
			#sound-dai-cells = <0x00000000>;
			status = "disabled";
			phandle = <0x00000076>;
		};
		pwmdac-transmitter {
			compatible = "linux,pwmdac-dit";
			#sound-dai-cells = <0x00000000>;
			status = "disabled";
			phandle = <0x0000002f>;
		};
		dmic_codec {
			compatible = "dmic-codec";
			#sound-dai-cells = <0x00000000>;
			status = "disabled";
			phandle = <0x00000077>;
		};
		spi@10060000 {
			compatible = "arm,pl022", "arm,primecell";
			reg = <0x00000000 0x10060000 0x00000000 0x00010000>;
			clocks = <0x0000000f 0x00000083>;
			clock-names = "apb_pclk";
			resets = <0x00000010 0x00000045>;
			reset-names = "rst_apb";
			interrupts = <0x00000026>;
			dmas = <0x0000001b 0x0000000e 0x00000001 0x0000001b 0x0000000f 0x00000001>;
			dma-names = "rx", "tx";
			arm,primecell-periphid = <0x00041022>;
			num-cs = <0x00000001>;
			#address-cells = <0x00000001>;
			#size-cells = <0x00000000>;
			status = "disabled";
			phandle = <0x00000078>;
		};
		pcie@2B000000 {
			compatible = "starfive,jh7110-pcie";
			#address-cells = <0x00000003>;
			#size-cells = <0x00000002>;
			#interrupt-cells = <0x00000001>;
			reg = <0x00000000 0x2b000000 0x00000000 0x01000000 0x00000009 0x40000000 0x00000000 0x10000000>;
			reg-names = "reg", "config";
			device_type = "pci";
			starfive,stg-syscon = <0x00000011 0x000000c0 0x000000c4 0x00000130 0x000001b8>;
			bus-range = <0x00000000 0x000000ff>;
			ranges = <0x82000000 0x00000000 0x30000000 0x00000000 0x30000000 0x00000000 0x08000000 0xc3000000 0x00000009 0x00000000 0x00000009 0x00000000 0x00000000 0x40000000>;
			msi-parent = <0x00000002>;
			interrupts = <0x00000038>;
			interrupt-controller;
			interrupt-names = "msi";
			interrupt-parent = <0x00000002>;
			interrupt-map-mask = <0x00000000 0x00000000 0x00000000 0x00000007>;
			interrupt-map = <0x00000000 0x00000000 0x00000000 0x00000001 0x00000002 0x00000001 0x00000000 0x00000000 0x00000000 0x00000002 0x00000002 0x00000002 0x00000000 0x00000000 0x00000000 0x00000003 0x00000002 0x00000003 0x00000000 0x00000000 0x00000000 0x00000004 0x00000002 0x00000004>;
			resets = <0x00000010 0x0000008b 0x00000010 0x0000008c 0x00000010 0x0000008d 0x00000010 0x0000008e 0x00000010 0x0000008f 0x00000010 0x00000090>;
			reset-names = "rst_mst0", "rst_slv0", "rst_slv", "rst_brg", "rst_core", "rst_apb";
			clocks = <0x0000000f 0x00000060 0x0000000f 0x000000c8 0x0000000f 0x000000c6 0x0000000f 0x000000c7>;
			clock-names = "noc", "tl", "axi_mst0", "apb";
			status = "disabled";
			pinctrl-names = "perst-default", "perst-active";
			pinctrl-0 = <0x0000001c>;
			pinctrl-1 = <0x0000001d 0x0000001e 0x0000001f>;
			phandle = <0x00000079>;
		};
		pcie@2C000000 {
			compatible = "starfive,jh7110-pcie";
			#address-cells = <0x00000003>;
			#size-cells = <0x00000002>;
			#interrupt-cells = <0x00000001>;
			reg = <0x00000000 0x2c000000 0x00000000 0x01000000 0x00000009 0xc0000000 0x00000000 0x10000000>;
			reg-names = "reg", "config";
			device_type = "pci";
			starfive,stg-syscon = <0x00000011 0x00000270 0x00000274 0x000002e0 0x00000368>;
			bus-range = <0x00000000 0x000000ff>;
			ranges = <0x82000000 0x00000000 0x38000000 0x00000000 0x38000000 0x00000000 0x08000000 0xc3000000 0x00000009 0x80000000 0x00000009 0x80000000 0x00000000 0x40000000>;
			msi-parent = <0x00000002>;
			interrupts = <0x00000039>;
			interrupt-controller;
			interrupt-names = "msi";
			interrupt-parent = <0x00000002>;
			interrupt-map-mask = <0x00000000 0x00000000 0x00000000 0x00000007>;
			interrupt-map = <0x00000000 0x00000000 0x00000000 0x00000001 0x00000002 0x00000001 0x00000000 0x00000000 0x00000000 0x00000002 0x00000002 0x00000002 0x00000000 0x00000000 0x00000000 0x00000003 0x00000002 0x00000003 0x00000000 0x00000000 0x00000000 0x00000004 0x00000002 0x00000004>;
			resets = <0x00000010 0x00000091 0x00000010 0x00000092 0x00000010 0x00000093 0x00000010 0x00000094 0x00000010 0x00000095 0x00000010 0x00000096>;
			reset-names = "rst_mst0", "rst_slv0", "rst_slv", "rst_brg", "rst_core", "rst_apb";
			clocks = <0x0000000f 0x00000060 0x0000000f 0x000000cb 0x0000000f 0x000000c9 0x0000000f 0x000000ca>;
			clock-names = "noc", "tl", "axi_mst0", "apb";
			status = "okay";
			pinctrl-names = "perst-default", "perst-active";
			pinctrl-0 = <0x00000020>;
			pinctrl-1 = <0x00000021 0x00000022 0x00000023>;
			phandle = <0x0000007a>;
		};
		mailbox@0 {
			compatible = "starfive,mail_box";
			reg = <0x00000000 0x13060000 0x00000000 0x00001000>;
			clocks = <0x0000000f 0x00000071>;
			clock-names = "clk_apb";
			resets = <0x00000010 0x00000044>;
			reset-names = "mbx_rre";
			interrupts = <0x0000001a 0x0000001b>;
			#mbox-cells = <0x00000002>;
			status = "disabled";
			phandle = <0x00000024>;
		};
		mailbox_client@0 {
			compatible = "starfive,mailbox-test";
			mbox-names = "rx", "tx";
			mboxes = <0x00000024 0x00000000 0x00000001 0x00000024 0x00000001 0x00000000>;
			status = "disabled";
			phandle = <0x0000007b>;
		};
		dssctrl@295B0000 {
			compatible = "verisilicon,dss-ctrl", "syscon";
			reg = <0x00000000 0x295b0000 0x00000000 0x00000090>;
			phandle = <0x0000002c>;
		};
		dc8200@29400000 {
			compatible = "starfive,sf-dc8200";
			reg = <0x00000000 0x29400000 0x00000000 0x00000100 0x00000000 0x29400800 0x00000000 0x00002000>;
			reg-names = "hi", "low";
			status = "okay";
			clocks = <0x0000000f 0x0000003c 0x0000000f 0x0000003a 0x0000000f 0x0000003e 0x0000000f 0x0000003d 0x00000025 0x00000169 0x00000025 0x0000016a 0x00000025 0x00000166 0x00000025 0x00000167 0x00000025 0x00000168 0x00000025 0x0000016b 0x0000000c 0x00000025 0x00000163 0x00000025 0x00000189 0x00000025 0x0000018a>;
			clock-names = "disp_axi", "vout_src", "top_vout_axi", "top_vout_ahb", "dc_pix0", "dc_pix1", "dc_axi", "dc_core", "dc_ahb", "top_vout_lcd", "hdmitx0_pixelclk", "dc8200_pix0", "dc8200_pix0_out", "dc8200_pix1_out";
			resets = <0x00000010 0x0000002b 0x00000010 0x000000e0 0x00000010 0x000000e1 0x00000010 0x000000e2 0x00000010 0x0000001a>;
			reset-names = "rst_vout_src", "rst_axi", "rst_ahb", "rst_core", "rst_noc_disp";
			phandle = <0x0000007c>;
			port {
				#address-cells = <0x00000001>;
				#size-cells = <0x00000000>;
				phandle = <0x0000007d>;
				endpoint@0 {
					reg = <0x00000000>;
					remote-endpoint = <0x00000026>;
					phandle = <0x00000029>;
				};
				endpoint@1 {
					reg = <0x00000001>;
					remote-endpoint = <0x00000027>;
					phandle = <0x0000002b>;
				};
			};
		};
		hdmi@29590000 {
			compatible = "starfive,inno-hdmi";
			reg = <0x00000000 0x29590000 0x00000000 0x00004000>;
			status = "okay";
			clocks = <0x00000025 0x00000173 0x00000025 0x00000171 0x00000025 0x00000172>;
			clock-names = "sysclk", "mclk", "bclk";
			resets = <0x00000010 0x000000e9>;
			reset-names = "hdmi_tx";
			pinctrl-names = "default";
			pinctrl-0 = <0x00000028>;
			phandle = <0x0000007e>;
			ports {
				port {
					#address-cells = <0x00000001>;
					#size-cells = <0x00000000>;
					phandle = <0x0000007f>;
					endpoint@0 {
						reg = <0x00000000>;
						remote-endpoint = <0x00000029>;
						phandle = <0x00000026>;
					};
				};
			};
		};
		mipi@295d0000 {
			compatible = "starfive,sf_mipi_dsi";
			reg = <0x00000000 0x295d0000 0x00000000 0x00010000 0x00000000 0x295e0000 0x00000000 0x00010000 0x00000000 0x17010000 0x00000000 0x00001000>;
			reg-names = "dsi", "phy", "syscon";
			clocks = <0x00000025 0x0000016d 0x00000025 0x0000016c 0x00000025 0x0000016f 0x00000025 0x0000016e 0x00000025 0x00000170>;
			clock-names = "sys", "apb", "txesc", "dpi", "dphy_txesc";
			resets = <0x00000010 0x000000e3 0x00000010 0x000000e4 0x00000010 0x000000e5 0x00000010 0x000000e6 0x00000010 0x000000e7 0x00000010 0x000000e8 0x00000010 0x000000ea 0x00000010 0x000000eb>;
			reset-names = "dsi_dpi", "dsi_apb", "dsi_rxesc", "dsi_sys", "dsi_txbytehs", "dsi_txesc", "dphy_sys", "dphy_txbytehs";
			status = "okay";
			rockchip,panel = <0x0000002a>;
			data-lanes-num = <0x00000001>;
			phandle = <0x00000080>;
			ports {
				port {
					#address-cells = <0x00000001>;
					#size-cells = <0x00000000>;
					phandle = <0x00000081>;
					endpoint@0 {
						reg = <0x00000000>;
						remote-endpoint = <0x0000002b>;
						phandle = <0x00000027>;
					};
				};
			};
			display-timings {
				timing0 {
					bits-per-pixel = <0x00000018>;
					clock-frequency = <0x09896800>;
					hfront-porch = <0x00000078>;
					hsync-len = <0x00000014>;
					hback-porch = <0x00000015>;
					hactive = <0x000004b0>;
					vfront-porch = <0x00000015>;
					vsync-len = <0x00000003>;
					vback-porch = <0x00000012>;
					vactive = <0x00000780>;
					hsync-active = <0x00000000>;
					vsync-active = <0x00000000>;
					de-active = <0x00000001>;
					pixelclk-active = <0x00000000>;
				};
			};
		};
		dsi-host {
			compatible = "starfive,mipi-dsi";
			status = "okay";
			phandle = <0x00000082>;
		};
		hdmi-output {
			compatible = "verisilicon,hdmi-encoder";
			verisilicon,dss-syscon = <0x0000002c>;
			verisilicon,mux-mask = <0x00000070 0x00000380>;
			verisilicon,mux-val = <0x00000040 0x00000280>;
			status = "disabled";
			phandle = <0x00000083>;
		};
		mipi-dphy@295e0000 {
			compatible = "starfive,jh7100-mipi-dphy-tx";
			reg = <0x00000000 0x295e0000 0x00000000 0x00010000>;
			clocks = <0x00000025 0x00000170>;
			clock-names = "dphy_txesc";
			resets = <0x00000010 0x000000ea 0x00000010 0x000000eb>;
			reset-names = "dphy_sys", "dphy_txbytehs";
			#phy-cells = <0x00000000>;
			status = "disabled";
			phandle = <0x00000084>;
		};
		snd-card {
			compatible = "simple-audio-card";
			simple-audio-card,name = "Starfive-Multi-Sound-Card";
			#address-cells = <0x00000001>;
			#size-cells = <0x00000000>;
			phandle = <0x00000085>;
			simple-audio-card,dai-link@0 {
				reg = <0x00000000>;
				format = "left_j";
				bitclock-master = <0x0000002d>;
				frame-master = <0x0000002d>;
				status = "okay";
				cpu {
					sound-dai = <0x0000002e>;
					phandle = <0x0000002d>;
				};
				codec {
					sound-dai = <0x0000002f>;
				};
			};
		};
		e24@0 {
			compatible = "starfive,e24";
			reg = <0x00000000 0xc0110000 0x00000000 0x00001000 0x00000000 0xc0111000 0x00000000 0x0001f000>;
			reg-names = "ecmd", "espace";
			clocks = <0x0000000f 0x000000d6 0x0000000f 0x000000d7 0x0000000f 0x000000d8>;
			clock-names = "clk_rtc", "clk_core", "clk_dbg";
			resets = <0x00000010 0x00000084>;
			reset-names = "e24_core";
			starfive,stg-syscon = <0x00000011>;
			interrupt-parent = <0x00000002>;
			firmware-name = "e24_elf";
			irq-mode = <0x00000001>;
			mbox-names = "tx", "rx";
			mboxes = <0x00000024 0x00000000 0x00000002 0x00000024 0x00000002 0x00000000>;
			#address-cells = <0x00000001>;
			#size-cells = <0x00000001>;
			ranges = <0xc0000000 0x00000000 0xc0000000 0x00200000>;
			status = "disabled";
			phandle = <0x00000086>;
			dsp@0 {
			};
		};
		dmc@100b0000 {
			compatible = "starfive,jh7110-dmc";
			reg = <0x00000000 0x15700000 0x00000000 0x00010000 0x00000000 0x13000000 0x00000000 0x00010000>;
			resets = <0x00000010 0x00000026 0x00000010 0x00000027 0x00000010 0x00000028>;
			reset-names = "axi", "osc", "apb";
			clock-frequency = <0x00000855>;
			u-boot,dm-spl;
			phandle = <0x00000087>;
		};
	};
	aliases {
		spi0 = "/soc/spi@13010000";
		gpio0 = "/soc/gpio@13040000";
		ethernet0 = "/soc/ethernet@16030000";
		ethernet1 = "/soc/ethernet@16040000";
		mmc0 = "/soc/sdio0@16010000";
		mmc1 = "/soc/sdio1@16020000";
		i2c0 = "/soc/i2c5@12050000";
	};
	chosen {
		stdout-path = "/soc/serial@10000000:115200";
		starfive,boot-hart-id = <0x00000001>;
		u-boot,dm-spl;
	};
	memory@80000000 {
		device_type = "memory";
		reg = <0x00000000 0x40000000 0x00000001 0x00000000>;
		u-boot,dm-spl;
	};
	gpio-restart {
		compatible = "gpio-restart";
		gpios = <0x00000030 0x00000023 0x00000000>;
	};
	firmware {
		spi0 = "/soc/qspi@11860000";
		u-boot,dm-spl;
	};
	config {
		u-boot,dm-spl;
		u-boot,spl-payload-offset = <0x00100000>;
	};
	__symbols__ {
		osc = "/osc";
		gmac1_rmii_refin = "/gmac1_rmii_refin";
		gmac1_rgmii_rxin = "/gmac1_rgmii_rxin";
		i2stx_bclk_ext = "/i2stx_bclk_ext";
		i2stx_lrck_ext = "/i2stx_lrck_ext";
		i2srx_bclk_ext = "/i2srx_bclk_ext";
		i2srx_lrck_ext = "/i2srx_lrck_ext";
		tdm_ext = "/tdm_ext";
		mclk_ext = "/mclk_ext";
		jtag_tck_inner = "/jtag_tck_inner";
		bist_apb = "/bist_apb";
		stg_apb = "/stg_apb";
		gmac0_rmii_refin = "/gmac0_rmii_refin";
		gmac0_rgmii_rxin = "/gmac0_rgmii_rxin";
		clk_rtc = "/clk_rtc";
		hdmitx0_pixelclk = "/hdmitx0_pixelclk";
		mipitx_dphy_rxesc = "/mipitx_dphy_rxesc";
		mipitx_dphy_txbytehs = "/mipitx_dphy_txbytehs";
		cpus = "/cpus";
		cpu0 = "/cpus/cpu@0";
		cpu0intctrl = "/cpus/cpu@0/interrupt-controller";
		cpu1 = "/cpus/cpu@1";
		cpu1intctrl = "/cpus/cpu@1/interrupt-controller";
		cpu2 = "/cpus/cpu@2";
		cpu2intctrl = "/cpus/cpu@2/interrupt-controller";
		cpu3 = "/cpus/cpu@3";
		cpu3intctrl = "/cpus/cpu@3/interrupt-controller";
		cpu4 = "/cpus/cpu@4";
		cpu4intctrl = "/cpus/cpu@4/interrupt-controller";
		soc = "/soc";
		cachectrl = "/soc/cache-controller@2010000";
		aon_syscon = "/soc/aon_syscon@17010000";
		stg_syscon = "/soc/stg_syscon@10240000";
		sys_syscon = "/soc/sys_syscon@13030000";
		clint = "/soc/clint@2000000";
		plic = "/soc/plic@c000000";
		clkgen = "/soc/clock-controller";
		clkvout = "/soc/clock-controller@295C0000";
		clkisp = "/soc/clock-controller@19810000";
		qspi = "/soc/spi@13010000";
		nor_flash = "/soc/spi@13010000/nor-flash@0";
		otp = "/soc/otp@17050000";
		usbdrd30 = "/soc/usbdrd";
		usbdrd_cdns3 = "/soc/usbdrd/usb@10100000";
		timer = "/soc/timer@13050000";
		wdog = "/soc/wdog@13070000";
		rtc = "/soc/rtc@17040000";
		pmu = "/soc/pmu@17030000";
		uart0 = "/soc/serial@10000000";
		uart1 = "/soc/serial@10010000";
		uart2 = "/soc/serial@10020000";
		uart3 = "/soc/serial@12000000";
		uart4 = "/soc/serial@12010000";
		uart5 = "/soc/serial@12020000";
		dma = "/soc/dma-controller@16050000";
		gpio = "/soc/gpio@13040000";
		uart0_pins = "/soc/gpio@13040000/uart0-0";
		mmc0_pins = "/soc/gpio@13040000/mmc0-pins";
		sdcard1_pins = "/soc/gpio@13040000/sdcard1-pins";
		pcie0_perst_default = "/soc/gpio@13040000/pcie0_perst_default";
		pcie0_perst_active = "/soc/gpio@13040000/pcie0_perst_active";
		pcie0_wake_default = "/soc/gpio@13040000/pcie0_wake_default";
		pcie0_clkreq_default = "/soc/gpio@13040000/pcie0_clkreq_default";
		pcie1_perst_default = "/soc/gpio@13040000/pcie1_perst_default";
		pcie1_perst_active = "/soc/gpio@13040000/pcie1_perst_active";
		pcie1_wake_default = "/soc/gpio@13040000/pcie1_wake_default";
		pcie1_clkreq_default = "/soc/gpio@13040000/pcie1_clkreq_default";
		i2c2_pins = "/soc/gpio@13040000/i2c2-0";
		i2c5_pins = "/soc/gpio@13040000/i2c5-0";
		hdmi_pins = "/soc/gpio@13040000/hdmi-0";
		usb0_pins = "/soc/gpio@13040000/usb0-0";
		gpioa = "/soc/gpio@17020000";
		trng = "/soc/trng@1600C000";
		sec_dma = "/soc/sec_dma@16008000";
		crypto = "/soc/crypto@16000000";
		i2c0 = "/soc/i2c@10030000";
		i2c1 = "/soc/i2c@10040000";
		i2c2 = "/soc/i2c@10050000";
		rm68200_panel = "/soc/i2c@10050000/rm68200_panel@45";
		i2c3 = "/soc/i2c@12030000";
		i2c4 = "/soc/i2c@12040000";
		i2c5 = "/soc/i2c5@12050000";
		pmic = "/soc/i2c5@12050000/axp15060_reg@36";
		i2c6 = "/soc/i2c@12060000";
		sdio0 = "/soc/sdio0@16010000";
		sdio1 = "/soc/sdio1@16020000";
		vin_sysctl = "/soc/vin_sysctl@19800000";
		jpu = "/soc/jpu@11900000";
		vpu_dec = "/soc/vpu_dec@130A0000";
		vpu_enc = "/soc/vpu_enc@130B0000";
		rstgen = "/soc/reset-controller";
		stmmac_axi_setup = "/soc/stmmac-axi-config";
		gmac0 = "/soc/ethernet@16030000";
		phy0 = "/soc/ethernet@16030000/ethernet-phy@0";
		gmac1 = "/soc/ethernet@16040000";
		phy1 = "/soc/ethernet@16040000/ethernet-phy@1";
		gpu = "/soc/gpu@18000000";
		can0 = "/soc/can@130d0000";
		can1 = "/soc/can@130e0000";
		tdm = "/soc/tdm@10090000";
		spdif0 = "/soc/spdif0@100a0000";
		pwmdac = "/soc/pwmdac@100b0000";
		i2stx = "/soc/i2stx@100c0000";
		pdm = "/soc/pdm@100d0000";
		i2srx_3ch = "/soc/i2srx_3ch@100e0000";
		i2stx_4ch0 = "/soc/i2stx_4ch0@120b0000";
		i2stx_4ch1 = "/soc/i2stx_4ch1@120c0000";
		ptc = "/soc/pwm@120d0000";
		spdif_transmitter = "/soc/spdif_transmitter";
		spdif_receiver = "/soc/spdif_receiver";
		pwmdac_codec = "/soc/pwmdac-transmitter";
		dmic_codec = "/soc/dmic_codec";
		spi0 = "/soc/spi@10060000";
		pcie0 = "/soc/pcie@2B000000";
		pcie1 = "/soc/pcie@2C000000";
		mailbox_contrl0 = "/soc/mailbox@0";
		mailbox_client0 = "/soc/mailbox_client@0";
		dssctrl = "/soc/dssctrl@295B0000";
		dc8200 = "/soc/dc8200@29400000";
		vopb_out = "/soc/dc8200@29400000/port";
		vopb_out_hdmi = "/soc/dc8200@29400000/port/endpoint@0";
		vopb_out_mipi = "/soc/dc8200@29400000/port/endpoint@1";
		hdmi = "/soc/hdmi@29590000";
		hdmi_in = "/soc/hdmi@29590000/ports/port";
		hdmi_in_vopb = "/soc/hdmi@29590000/ports/port/endpoint@0";
		mipi_dsi0 = "/soc/mipi@295d0000";
		mipi_in = "/soc/mipi@295d0000/ports/port";
		mipi_in_vopb = "/soc/mipi@295d0000/ports/port/endpoint@0";
		dsi_host = "/soc/dsi-host";
		hdmi_output = "/soc/hdmi-output";
		mipi_dphy = "/soc/mipi-dphy@295e0000";
		sound = "/soc/snd-card";
		sndcpu0 = "/soc/snd-card/simple-audio-card,dai-link@0/cpu";
		co_process = "/soc/e24@0";
		dmc = "/soc/dmc@100b0000";
	};
};
